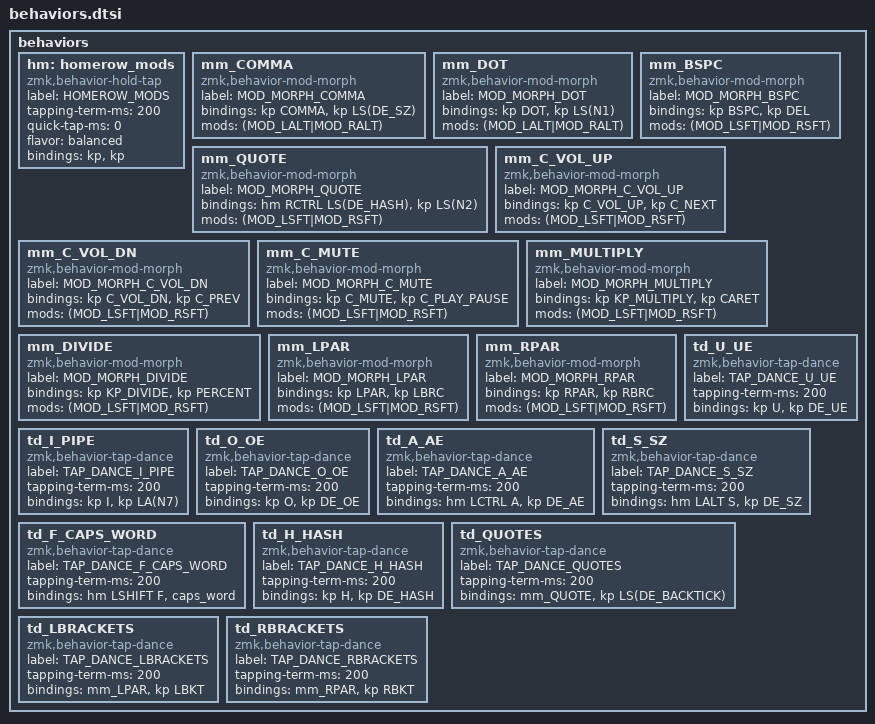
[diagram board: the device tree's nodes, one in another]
behaviors {
    hm: homerow_mods {
        compatible = "zmk,behavior-hold-tap";
        label = "HOMEROW_MODS";
        #binding-cells = <2>;
        tapping-term-ms = <200>;
        quick-tap-ms = <0>;
        flavor = "balanced";
        bindings = <&kp>, <&kp>;
    };

    mm_COMMA: mm_COMMA {
        compatible = "zmk,behavior-mod-morph";
        label = "MOD_MORPH_COMMA";
        #binding-cells = <0>;
        bindings = <&kp COMMA>, <&kp LS(DE_SZ)>;
        mods = <(MOD_LALT|MOD_RALT)>;
    };
    mm_DOT: mm_DOT {
        compatible = "zmk,behavior-mod-morph";
        label = "MOD_MORPH_DOT";
        #binding-cells = <0>;
        bindings = <&kp DOT>, <&kp LS(N1)>;
        mods = <(MOD_LALT|MOD_RALT)>;
    };
    mm_QUOTE: mm_QUOTE {
        compatible = "zmk,behavior-mod-morph";
        label = "MOD_MORPH_QUOTE";
        #binding-cells = <0>;
        bindings = <&hm RCTRL LS(DE_HASH)>, <&kp LS(N2)>;
        mods = <(MOD_LSFT|MOD_RSFT)>;
    };
    mm_BSPC: mm_BSPC {
        compatible = "zmk,behavior-mod-morph";
        label = "MOD_MORPH_BSPC";
        #binding-cells = <0>;
        bindings = <&kp BSPC>, <&kp DEL>;
        mods = <(MOD_LSFT|MOD_RSFT)>;
    };

    mm_C_VOL_UP: mm_C_VOL_UP {
        compatible = "zmk,behavior-mod-morph";
        label = "MOD_MORPH_C_VOL_UP";
        #binding-cells = <0>;
        bindings = <&kp C_VOL_UP>, <&kp C_NEXT>;
        mods = <(MOD_LSFT|MOD_RSFT)>;
    };
    mm_C_VOL_DN: mm_C_VOL_DN {
        compatible = "zmk,behavior-mod-morph";
        label = "MOD_MORPH_C_VOL_DN";
        #binding-cells = <0>;
        bindings = <&kp C_VOL_DN>, <&kp C_PREV>;
        mods = <(MOD_LSFT|MOD_RSFT)>;
    };
    mm_C_MUTE: mm_C_MUTE {
        compatible = "zmk,behavior-mod-morph";
        label = "MOD_MORPH_C_MUTE";
        #binding-cells = <0>;
        bindings = <&kp C_MUTE>, <&kp C_PLAY_PAUSE>;
        mods = <(MOD_LSFT|MOD_RSFT)>;
    };

    mm_MULTIPLY: mm_MULTIPLY {
        compatible = "zmk,behavior-mod-morph";
        label = "MOD_MORPH_MULTIPLY";
        #binding-cells = <0>;
        bindings = <&kp KP_MULTIPLY>, <&kp CARET>;
        mods = <(MOD_LSFT|MOD_RSFT)>;
    };
    mm_DIVIDE: mm_DIVIDE {
        compatible = "zmk,behavior-mod-morph";
        label = "MOD_MORPH_DIVIDE";
        #binding-cells = <0>;
        bindings = <&kp KP_DIVIDE>, <&kp PERCENT>;
        mods = <(MOD_LSFT|MOD_RSFT)>;
    };
    mm_LPAR: mm_LPAR {
        compatible = "zmk,behavior-mod-morph";
        label = "MOD_MORPH_LPAR";
        #binding-cells = <0>;
        bindings = <&kp LPAR>, <&kp LBRC>;
        mods = <(MOD_LSFT|MOD_RSFT)>;
    };
    mm_RPAR: mm_RPAR {
        compatible = "zmk,behavior-mod-morph";
        label = "MOD_MORPH_RPAR";
        #binding-cells = <0>;
        bindings = <&kp RPAR>, <&kp RBRC>;
        mods = <(MOD_LSFT|MOD_RSFT)>;
    };

    td_U_UE: td_U_UE {
        compatible = "zmk,behavior-tap-dance";
        label = "TAP_DANCE_U_UE";
        #binding-cells = <0>;
        tapping-term-ms = <200>;
        bindings = <&kp U>, <&kp DE_UE>;
    };
    td_I_PIPE: td_I_PIPE {
        compatible = "zmk,behavior-tap-dance";
        label = "TAP_DANCE_I_PIPE";
        #binding-cells = <0>;
        tapping-term-ms = <200>;
        bindings = <&kp I>, <&kp LA(N7)>;
    };
    td_O_OE: td_O_OE {
        compatible = "zmk,behavior-tap-dance";
        label = "TAP_DANCE_O_OE";
        #binding-cells = <0>;
        tapping-term-ms = <200>;
        bindings = <&kp O>, <&kp DE_OE>;
    };
    td_A_AE: td_A_AE {
        compatible = "zmk,behavior-tap-dance";
        label = "TAP_DANCE_A_AE";
        #binding-cells = <0>;
        tapping-term-ms = <200>;
        bindings = <&hm LCTRL A>, <&kp DE_AE>;
    };
    td_S_SZ: td_S_SZ {
        compatible = "zmk,behavior-tap-dance";
        label = "TAP_DANCE_S_SZ";
        #binding-cells = <0>;
        tapping-term-ms = <200>;
        bindings = <&hm LALT S>, <&kp DE_SZ>;
    };
    td_F_CAPS_WORD: td_F_CAPS_WORD {
        compatible = "zmk,behavior-tap-dance";
        label = "TAP_DANCE_F_CAPS_WORD";
        #binding-cells = <0>;
        tapping-term-ms = <200>;
        bindings = <&hm LSHIFT F>, <&caps_word>;
    };
    td_H_HASH: td_H_HASH {
        compatible = "zmk,behavior-tap-dance";
        label = "TAP_DANCE_H_HASH";
        #binding-cells = <0>;
        tapping-term-ms = <200>;
        bindings = <&kp H>, <&kp DE_HASH>;
    };
    td_QUOTES: td_QUOTES {
        compatible = "zmk,behavior-tap-dance";
        label = "TAP_DANCE_QUOTES";
        #binding-cells = <0>;
        tapping-term-ms = <200>;
        bindings = <&mm_QUOTE>, <&kp LS(DE_BACKTICK)>;
    };

    td_LBRACKETS: td_LBRACKETS {
        compatible = "zmk,behavior-tap-dance";
        label = "TAP_DANCE_LBRACKETS";
        #binding-cells = <0>;
        tapping-term-ms = <200>;
        bindings = <&mm_LPAR>, <&kp LBKT>;
    };
    td_RBRACKETS: td_RBRACKETS {
        compatible = "zmk,behavior-tap-dance";
        label = "TAP_DANCE_RBRACKETS";
        #binding-cells = <0>;
        tapping-term-ms = <200>;
        bindings = <&mm_RPAR>, <&kp RBKT>;
    };
};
